# i2c1_secure register map
Vendor: Texas Instruments
Peripheral module from a debugger description file (folder CC35X1E).
Registers are 32-bit, access per field, reset values left out (the file's numbers can be read two ways) unless marked. A register's access mark holds for its fields unless they carry their own. Offsets are as the file gives them; lines under a group give offsets from that group; [hi:lo] are bit positions; {n}, {i} and the like mark numbered series; 'fields as' and 'values as' point back to an identical list; <NAME> marks a mode.

## i2c1_secure
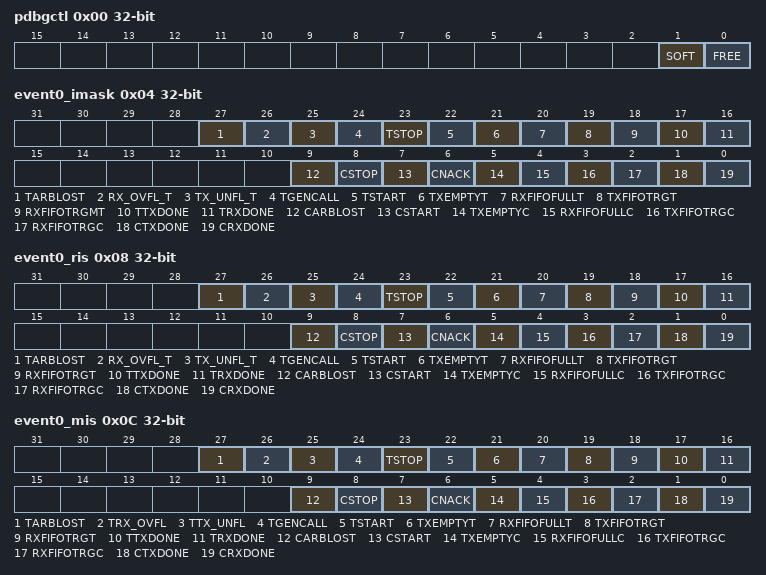
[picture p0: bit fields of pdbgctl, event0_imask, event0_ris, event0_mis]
0x00 pdbgctl — This register can be used by the software developer to control the behavior of the peripheral relative to the 'Core Halted' input
  [1] SOFT rw — Soft halt boundary control. This function is only available, if FREE is set to 'STOP'
    0=DIS (The peripheral will halt immediately, even if the resultant state will result in corruption if the system is restarted); 1=EN (The peripheral blocks the debug freeze until it has reached a boundary where it can resume without corruption)
  [0] FREE rw — Free run control
    0=DIS (The peripheral freezes functionality while the Core Halted input is asserted and resumes when it is deasserted.); 1=EN (The peripheral ignores the state of the Core Halted input)
0x04 event0_imask — Interrupt Mask. If a field is set, then corresponding interrupt is masked. Un-masking the interrupt causes the raw interrupt to be visible in [RIS], as well as [MIS].
  [27] TARBLOST rw — Target arbitration lost
    1=EN (Set Interrupt Mask); 0=DIS (Clear Interrupt Mask)
  [26] RX_OVFL_T rw — RX FIFO overflow in target mode
    1=EN (Set Interrupt Mask); 0=DIS (Clear Interrupt Mask)
  [25] TX_UNFL_T rw — TX FIFO underflow in target mode
    1=EN (Set Interrupt Mask); 0=DIS (Clear Interrupt Mask)
  [24] TGENCALL rw — General call interrupt
    1=EN (Set Interrrupt Mask); 0=DIS (Clear Interrupt Mask)
  [23] TSTOP rw — Stop condition interrupt
    1=EN (Set Interrrupt Mask); 0=DIS (Clear Interrupt Mask)
  [22] TSTART rw — Target start condition interrupt. Asserted when the received address matches the target address
    1=EN (Set Interrrupt Mask); 0=DIS (Clear Interrupt Mask)
  [21] TXEMPTYT rw — TX FIFO empty interrupt mask in target mode. This interrupt is set if all data in the Transmit FIFO in target mode have been shifted out and the transmit goes into idle mode.
    1=EN (Set Interrrupt Mask); 0=DIS (Clear Interrupt Mask)
  [20] RXFIFOFULLT rw — RX FIFO full event. This interrupt is set if an target RX FIFO is full in target mode.
    1=EN (Set Interrrupt Mask); 0=DIS (Clear Interrupt Mask)
  [19] TXFIFOTRGT rw — TX FIFO trigger in target mode
    1=EN (Set Interrrupt Mask); 0=DIS (Clear Interrupt Mask)
  [18] RXFIFOTRGMT rw — RX FIFO trigger in target mode
    1=EN (Set Interrrupt Mask); 0=DIS (Clear Interrupt Mask)
  [17] TTXDONE rw — Target transmit transaction completed interrupt
    1=EN (Set Interrrupt Mask); 0=DIS (Clear Interrupt Mask)
  [16] TRXDONE rw — Target receive data interrupt. Signals that a byte has been received
    1=EN (Set Interrrupt Mask); 0=DIS (Clear Interrupt Mask)
  [9] CARBLOST rw — Arbitration lost interrupt
    1=EN (Set Interrrupt Mask); 0=DIS (Clear Interrupt Mask)
  [8] CSTOP rw — STOP detection interrupt
    1=EN (Set Interrrupt Mask); 0=DIS (Clear Interrupt Mask)
  [7] CSTART rw — START detection interrupt
    1=EN (Set Interrrupt Mask); 0=DIS (Clear Interrupt Mask)
  [6] CNACK rw — Address/Data NACK interrupt
    1=EN (Set Interrrupt Mask); 0=DIS (Clear Interrupt Mask)
  [5] TXEMPTYC rw — TXFIFO empty interrupt in controller mode. This interrupt is set if all data in the TX FIFO in controller mode have been shifted out and the transmit goes into idle mode.
    1=EN (Set Interrrupt Mask); 0=DIS (Clear Interrupt Mask)
  [4] RXFIFOFULLC rw — RXFIFO full event in controller mode. This interrupt is set if an RX FIFO is full in controller mode.
    1=EN (Set Interrrupt Mask); 0=DIS (Clear Interrupt Mask)
  [3] TXFIFOTRGC rw — Transmit FIFO trigger in controller mode Trigger when TX FIFO contains <= defined bytes
    1=EN (Set Interrrupt Mask); 0=DIS (Clear Interrupt Mask)
  [2] RXFIFOTRGC rw — Receive FIFO trigger in controller code Trigger when RX FIFO contains >= defined bytes
    1=EN (Set Interrrupt Mask); 0=DIS (Clear Interrupt Mask)
  [1] CTXDONE rw — Controller transmit transaction completed Interrupt
    1=EN (Set Interrrupt Mask); 0=DIS (Clear Interrupt Mask)
  [0] CRXDONE rw — Controller receive transaction completed Interrupt
    1=EN (Set Interrrupt Mask); 0=DIS (Clear Interrupt Mask)
0x08 event0_ris ro — Raw interrupt status. Reflects all pending interrupts, regardless of masking. The RIS register allows the user to implement a poll scheme. A flag set in this register can be cleared by writing 1 to the [ICLR] register field even if the corresponding [IMASK] field is not enabled.
  [27] TARBLOST — Target arbitration lost
    1=SET (Interrupt occured); 0=CLR (Interrupt did not occur)
  [26] RX_OVFL_T — RX FIFO overflow in target mode
    1=SET (Interrupt Occured); 0=CLR (Interrupt did not occur)
  [25] TX_UNFL_T — TX FIFO underflow in target mode
    1=SET (Interrupt occured); 0=CLR (Interrupt did not occur)
  [24] TGENCALL — General call interrupt
    1=SET (Interrupt occured); 0=CLR (Interrupt did not occur)
  [23] TSTOP — Stop condition interrupt
    1=SET (Interrupt occured); 0=CLR (Interrupt did not occur)
  [22] TSTART — Target start condition interrupt.When the received address matches the target address, this interrupt asserted.
    1=SET (Interrupt occured); 0=CLR (Interrupt did not occur)
  [21] TXEMPTYT — TX FIFO empty interrupt mask in target mode. This interrupt is set if all data in the TX FIFO in target mode have been shifted out and the transmit goes into idle mode.
    1=SET (Interrupt occured); 0=CLR (Interrupt did not occur)
  [20] RXFIFOFULLT — RX FIFO full event in target mode. This interrupt is set if an RX FIFO is full in target mode.
    1=SET (Interrupt occured); 0=CLR (Interrupt did not occur)
  [19] TXFIFOTRGT — TX FIFO trigger in target mode
    1=SET (Interrupt occured); 0=CLR (Interrupt did not occur)
  [18] RXFIFOTRGT — RX FIFO trigger in target mode
    1=SET (Interrupt occured); 0=CLR (Interrupt did not occur)
  [17] TTXDONE — Target transmit transaction completed interrupt
    1=SET (Interrupt occured); 0=CLR (Interrupt did not occur)
  [16] TRXDONE — Target receive data interrupt. Signals that a byte has been received
    1=SET (Interrupt occured); 0=CLR (Interrupt did not occur)
  [9] CARBLOST — Arbitration lost interrupt
    1=SET (Interrupt occured); 0=CLR (Interrupt did not occur)
  [8] CSTOP — STOP detection interrupt
    1=SET (Interrupt occured); 0=CLR (Interrupt did not occur)
  [7] CSTART — START detection interrupt
    1=SET (Interrupt occured); 0=CLR (Interrupt did not occur)
  [6] CNACK — Address/Data NACK interrupt
    1=SET (Interrupt occured); 0=CLR (Interrupt did not occur)
  [5] TXEMPTYC — TX FIFO empty interrupt mask in controller mode. This interrupt is set if all data in the TX FIFO in controller mode have been shifted out and the transmit goes into idle mode.
    1=SET (Interrupt occured); 0=CLR (Interrupt did not occur)
  [4] RXFIFOFULLC — RX FIFO full event in controller mode. This interrupt is set if an RX FIFO is full in controller mode.
    1=SET (Interrupt occured); 0=CLR (Interrupt did not occur)
  [3] TXFIFOTRGC — TX FIFO Trigger in Transmit Mode Trigger when TX FIFO contains <= defined bytes
    1=SET (Interrupt occured); 0=CLR (Interrupt did not occur)
  [2] RXFIFOTRGC — RX FIFO trigger in controller mode Trigger when RX FIFO contains >= defined bytes
    1=SET (Interrupt occured); 0=CLR (Interrupt did not occur)
  [1] CTXDONE — Controller transmit transaction completed interrupt
    1=SET (Interrupt occured); 0=CLR (Interrupt did not occur)
  [0] CRXDONE — Controller receive transaction completed interrupt
    1=SET (Interrupt occured); 0=CLR (Interrupt did not occur)
0x0C event0_mis ro — Masked interrupt status. This is an AND of the [IMASK] and [RIS] registers.
  [27] TARBLOST — Target arbitration lost
    1=SET (Masked interrupt occured); 0=CLR (Clear interrupt mask)
  [26] TRX_OVFL — RX FIFO overflow in target mode
    1=SET (Masked interrupt occured); 0=CLR (Masked Interrupt did not occur)
  [25] TTX_UNFL — TX FIFO underflow in target mode
    values as TRX_OVFL
  [24] TGENCALL — General call interrupt
    values as TRX_OVFL
  [23] TSTOP — Target STOP detection interrupt
    values as TRX_OVFL
  [22] TSTART — Target start condition interrupt. Asserted when the received address matches the target address
    values as TRX_OVFL
  [21] TXEMPTYT — TX FIFO empty interrupt mask in target mode. This interrupt is set if all data in the TX FIFO in target mode have been shifted out and the transmit goes into idle mode.
    values as TRX_OVFL
  [20] RXFIFOFULLT — RXFIFO full event in Target mode. This interrupt is set if an RX FIFO is full in target mode.
    values as TRX_OVFL
  [19] TXFIFOTRGT — TX FIFO trigger in target mode
    values as TRX_OVFL
  [18] RXFIFOTRGT — Target RX FIFO trigger
    values as TRX_OVFL
  [17] TTXDONE — Target transmit transaction completed interrupt
    values as TRX_OVFL
  [16] TRXDONE — Target receive data interrupt. Signals that a byte has been received
    values as TRX_OVFL
  [9] CARBLOST — Arbitration lost interrupt
    values as TRX_OVFL
  [8] CSTOP — STOP detection interrupt
    values as TRX_OVFL
  [7] CSTART — START detection interrupt
    values as TRX_OVFL
  [6] CNACK — Address/Data NACK interrupt
    values as TRX_OVFL
  [5] TXEMPTYC — TX FIFO Empty interrupt mask in controller mode. This interrupt is set if all data in the TX FIFO in controller mode have been shifted out and the transmit goes into idle mode.
    values as TRX_OVFL
  [4] RXFIFOFULLC — RX FIFO full event. This interrupt is set if the RX FIFO is full in controller mode.
    values as TRX_OVFL
  [3] TXFIFOTRGC — TX FIFO trigger in controller mode Trigger when TX FIFO contains <= defined bytes
    values as TRX_OVFL
  [2] RXFIFOTRGC — RX FIFO trigger in controller mode Trigger when RX FIFO contains >= defined bytes
    values as TRX_OVFL
  [1] CTXDONE — Controller transmit transaction completed interrupt
    values as TRX_OVFL
  [0] CRXDONE — Controller receive data interrupt
    values as TRX_OVFL
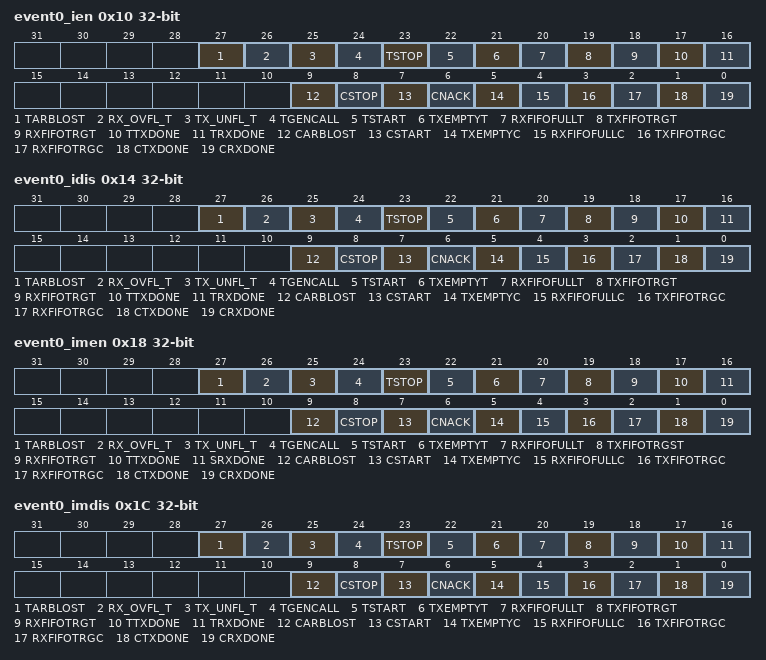
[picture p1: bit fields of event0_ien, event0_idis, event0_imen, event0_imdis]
0x10 event0_ien — Interrupt set. Allows interrupts to be set by software (useful in diagnostics and safety checks). Writing a 1 to a field in IEN will set the event and therefore the related RIS field also gets set. If the interrupt is enabled through the mask, then the corresponding MIS field is also set.
  [27] TARBLOST wo — Target arbitration lost
    1=EN (Set Interrupt); 0=DIS (Writing 0 has no effect)
  [26] RX_OVFL_T wo — RX FIFO overflow in target mode
    1=EN (Set Interrrupt); 0=DIS (Writing 0 has no effect)
  [25] TX_UNFL_T wo — TX FIFO underflow in target mode
    1=EN (Set interrupt); 0=DIS (Writing 0 has no effect)
  [24] TGENCALL wo — General call interrupt
    1=EN (Set Interrrupt); 0=DIS (Writing 0 has no effect)
  [23] TSTOP wo — Stop condition interrupt
    1=EN (Set Interrrupt); 0=DIS (Writing 0 has no effect)
  [22] TSTART wo — Target start condition interrupt. Asserted when the received address matches the target address
    1=EN (Set Interrrupt); 0=DIS (Writing 0 has no effect)
  [21] TXEMPTYT wo — TX FIFO empty interrupt mask in target mode. This interrupt is set if all data in the TX FIFO in target mode have been shifted out and the transmit goes into idle mode.
    1=EN (Set Interrrupt); 0=DIS (Writing 0 has no effect)
  [20] RXFIFOFULLT wo — RXFIFO full event in Target mode. This interrupt is set if an RX FIFO is full in Target mode.
    1=EN (Set Interrrupt); 0=DIS (Writing 0 has no effect)
  [19] TXFIFOTRGT wo — TX FIFO trigger in target mode
    1=EN (Set Interrrupt); 0=DIS (Writing 0 has no effect)
  [18] RXFIFOTRGT wo — RX FIFO trigger in target mode
    1=EN (Set Interrrupt); 0=DIS (Writing 0 has no effect)
  [17] TTXDONE wo — Target transmit transaction completed Interrupt
    1=EN (Set Interrrupt); 0=DIS (Writing 0 has no effect)
  [16] TRXDONE wo — Target receive data interrupt. Signals that a byte has been received
    1=EN (Set Interrrupt); 0=DIS (Writing 0 has no effect)
  [9] CARBLOST wo — Arbitration lost interrupt
    1=EN (Set Interrrupt); 0=DIS (Writing 0 has no effect)
  [8] CSTOP wo — STOP detection interrupt
    1=EN (Set Interrrupt); 0=DIS (Writing 0 has no effect)
  [7] CSTART wo — START detection interrupt
    1=EN (Set Interrrupt); 0=DIS (Writing 0 has no effect)
  [6] CNACK wo — Address/Data NACK interrupt
    1=EN (Set Interrrupt); 0=DIS (Writing 0 has no effect)
  [5] TXEMPTYC wo — TX FIFO empty interrupt mask in controller mode. This interrupt is set if all data in the TX FIFO in controller mode have been shifted out and the transmit goes into idle mode.
    1=EN (Set Interrrupt); 0=DIS (Writing 0 has no effect)
  [4] RXFIFOFULLC wo — RXFIFO full event in controller mode.
    1=EN (Set Interrrupt); 0=DIS (Writing 0 has no effect)
  [3] TXFIFOTRGC wo — TX FIFO trigger in controller mode Trigger when TX FIFO contains <= defined bytes
    1=EN (Set Interrrupt); 0=DIS (Writing 0 has no effect)
  [2] RXFIFOTRGC wo — RX FIFO trigger in controller mode Trigger when RX FIFO contains >= defined bytes
    1=EN (Set Interrrupt); 0=DIS (Writing 0 has no effect)
  [1] CTXDONE wo — Controller transmit transaction completed interrupt
    1=EN (Set Interrrupt); 0=DIS (Writing 0 has no effect)
  [0] CRXDONE wo — Controller receive data interrupt Signals that a byte has been received
    1=EN (Set Interrrupt); 0=DIS (Writing 0 has no effect)
0x14 event0_idis — Interrupt clear. Write a 1 to clear corresponding Interrupt.
  [all] fields
    1=EN (Clear Interrupt); 0=DIS (Writing 0 has no effect)
  [27] TARBLOST wo — Target arbitration lost
  [26] RX_OVFL_T wo — RX FIFO overflow in target mode
  [25] TX_UNFL_T wo — TX FIFO underflow in target mode
  [24] TGENCALL wo — General call interrupt
  [23] TSTOP wo — Target STOP detection interrupt
  [22] TSTART wo — Target start condition interrupt. Asserted when the received address matches the target address
  [21] TXEMPTYT wo — TX FIFO empty interrupt mask in target mode. This interrupt is set if all data in the TX FIFO in target mode have been shifted out and the transmit goes into idle mode.
  [20] RXFIFOFULLT wo — RXFIFO full event in target mode. This interrupt is set if an RX FIFO is full in target mode.
  [19] TXFIFOTRGT wo — TX FIFO trigger in target mode
  [18] RXFIFOTRGT wo — RX FIFO trigger in target mode
  [17] TTXDONE wo — Target transmit transaction completed interrupt
  [16] TRXDONE wo — Target receive data interrupt Signals that a byte has been received
  [9] CARBLOST wo — Arbitration lost interrupt
  [8] CSTOP wo — STOP detection interrupt
  [7] CSTART wo — START detection interrupt
  [6] CNACK wo — Address/Data NACK interrupt
  [5] TXEMPTYC wo — TX FIFO empty interrupt mask. This interrupt is set if all data in the TX FIFO have been shifted out and the transmit goes into idle mode.
  [4] RXFIFOFULLC wo — RXFIFO full event in controller mode.
  [3] TXFIFOTRGC wo — TX FIFO trigger in controller mode Trigger when TX FIFO contains <= defined bytes
  [2] RXFIFOTRGC wo — RX FIFO trigger in controller mode Trigger when RX FIFO contains >= defined bytes
  [1] CTXDONE wo — Controller transmit transaction completed interrupt
  [0] CRXDONE wo — Controller receive data interrupt. Signals that a byte has been received
0x18 event0_imen — Interrupt mask set. Writing a 1 to a field in IMEN will set the related IMASK field.
  [all] fields
    1=EN (Set masked interrrupt); 0=DIS (Writing 0 has no effect)
  [27] TARBLOST wo — Target srbitration lost
  [26] RX_OVFL_T wo — RX FIFO overflow in target mode
  [25] TX_UNFL_T wo — TX FIFO underflow in target mode
  [24] TGENCALL wo — General call interrupt
  [23] TSTOP wo — Stop condition interrupt
  [22] TSTART wo — Target start condition interrupt. Asserted when the received address matches the target address
  [21] TXEMPTYT wo — TX FIFO Empty interrupt mask in target mode. This interrupt is set if all data in the TX FIFO in target mode have been shifted out and the transmit goes into idle mode.
  [20] RXFIFOFULLT wo — RXFIFO full event in target mode. This interrupt is set if an RX FIFO is full in target mode.
  [19] TXFIFOTRGST wo — TX FIFO trigger in target mode
  [18] RXFIFOTRGT wo — RX FIFO trigger in target mode
  [17] TTXDONE wo — Target transmit transaction completed interrupt
  [16] SRXDONE wo — Target receive data interrupt. Signals that a byte has been received
  [9] CARBLOST wo — Arbitration lost interrupt
  [8] CSTOP wo — STOP detection interrupt
  [7] CSTART wo — START detection interrupt
  [6] CNACK wo — Address/Data NACK interrupt
  [5] TXEMPTYC wo — TX FIFO empty interrupt mask in controller mode. This interrupt is set if all data in the TX FIFO in controller mode have been shifted out and the transmit goes into idle mode.
  [4] RXFIFOFULLC wo — RXFIFO full event in controller mode.
  [3] TXFIFOTRGC wo — TX FIFO trigger in Controller mode Trigger when TX FIFO contains <= defined bytes
  [2] RXFIFOTRGC wo — RX FIFO trigger in controller mode Trigger when RX FIFO contains >= defined bytes
  [1] CTXDONE wo — Controller transmit transaction completed interrupt
  [0] CRXDONE wo — Controller receive data interrupt. Signals that a byte has been received
0x1C event0_imdis — Interrupt clear. Write a 1 to clear corresponding Interrupt.
  [all] fields
    1=EN (Clear masked interrupt); 0=DIS (Writing 0 has no effect)
  [27] TARBLOST wo — Target arbitration lost
  [26] RX_OVFL_T wo — RX FIFO overflow in target mode
  [25] TX_UNFL_T wo — TX FIFO underflow in target mode
  [24] TGENCALL wo — General call interrupt
  [23] TSTOP wo — Target STOP detection interrupt
  [22] TSTART wo — Target start condition interrupt. Asserted when the received address matches the target address.
  [21] TXEMPTYT wo — TX FIFO empty interrupt mask in target mode. This interrupt is set if all data in the TX FIFO in target mode have been shifted out and the transmit goes into idle mode.
  [20] RXFIFOFULLT wo — RXFIFO full event in target mode. This interrupt is set if an RX FIFO is full in target mode.
  [19] TXFIFOTRGT wo — TX FIFO trigger in target mode
  [18] RXFIFOTRGT wo — RX FIFO trigger in target mode
  [17] TTXDONE wo — Target transmit transaction completed interrupt
  [16] TRXDONE wo — Target receive data interrupt. Signals that a byte has been received
  [9] CARBLOST wo — Arbitration lost interrupt
  [8] CSTOP wo — STOP detection interrupt
  [7] CSTART wo — START detection interrupt
  [6] CNACK wo — Address/Data NACK interrupt
  [5] TXEMPTYC wo — TX FIFO empty interrupt mask. This interrupt is set if all data in the TX FIFO have been shifted out and the transmit goes into idle mode.
  [4] RXFIFOFULLC wo — RX FIFO full event in controller mode.
  [3] TXFIFOTRGC wo — TX FIFO trigger in controller mode Trigger when TX FIFO contains <= defined bytes
  [2] RXFIFOTRGC wo — RX FIFO trigger in controller mode Trigger when RX FIFO contains >= defined bytes
  [1] CTXDONE wo — Controller transmit transaction completed interrupt
  [0] CRXDONE wo — Controller receive data interrupt. Signals that a byte has been received
0x20 evt_mode ro — Event mode register. It is used to select whether each line is disabled, in software mode (software clears the [RIS]) or in hardware mode (hardware clears the [RIS])
  [1:0] INT0_CFG — Event line mode select for event corresponding to [INT_EVENT0]
    0=DIS (The interrupt or event line is disabled.); 1=SOFTWARE (The interrupt or event line is in software mode. Software must clear the RIS.); 2=HARDWARE (The interrupt or event line is in hardware mode. The hardware (another module) clears automatically the associated RIS flag.)
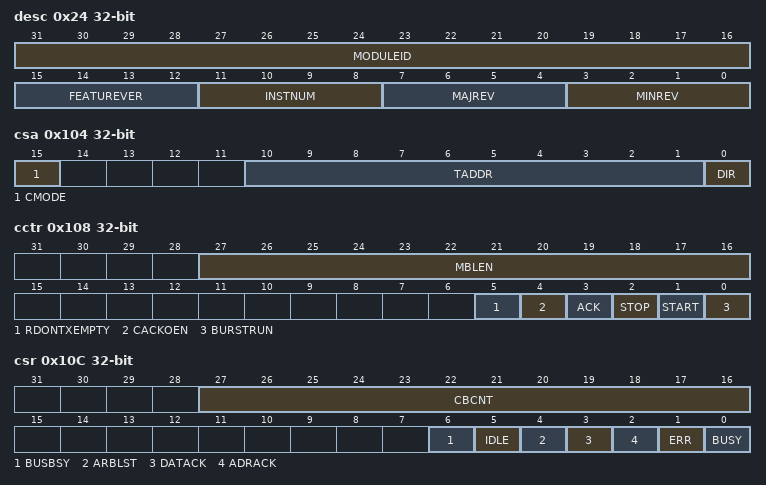
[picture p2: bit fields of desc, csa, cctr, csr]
0x24 desc ro — This register identifies the peripheral and its exact version.
  [31:16] MODULEID — Module identification contains a unique peripheral identification number. The assignments are maintained in a central database for all of the platform modules to ensure uniqueness.
    0=MINIMUM (Smallest value); 0xFFFF=MAXIMUM (Highest possible value)
  [15:12] FEATUREVER — Feature Set for the module *instance*
    0=MINIMUM (Smallest value); 15=MAXIMUM (Highest possible value)
  [11:8] INSTNUM — Instance Number within the device. This will be a parameter to the RTL for modules that can have multiple instances
    values as FEATUREVER
  [7:4] MAJREV — Major rev of the IP
    values as FEATUREVER
  [3:0] MINREV — Minor rev of the IP
    values as FEATUREVER
0x100 gfctl — This register controls the glitch filter on the SCL and SDA lines
  [3:0] GFSEL rw — Glitch suppression pulse width This field controls the pulse width select for glitch suppression on the SCL and SDA lines. The following values are the glitch suppression values in terms of functional clocks.
    0=DIS (Bypass); 1=CLK_1 (1 clock); {v}=CLK_{v} ({v} clocks) (v=2..8); 9=CLK_9 (10 clocks); 10=CLK_A (12 clocks); 11=CLK_B (14 clocks); 12=CLK_C (16 clocks); 13=CLK_D (20 clocks); 14=CLK_E (24 clocks); 15=CLK_F (31 clocks)
0x104 csa — Controller target address register
  [15] CMODE rw — This field selects the addressing mode(7-field/10-field) to be used in controller mode
    0=SEVEN_BIT (7-field addressing mode); 1=TEN_BIT (10-field addressing mode)
  [10:1] TADDR rw — *I2C* Target Address This field specifies bits A9 through A0 of the target address. In 7-field addressing mode as selected by MODE field, the top 3 bits are don't care
    0=MINIMUM (Smallest value); 0x3FF=MAXIMUM (Highest possible value)
  [0] DIR rw — This field specifies if the next controller operation is a Receive or Transmit
    0=TRANSMIT (The controller is in transmit mode.); 1=RECEIVE (The controller is in receive mode.)
0x108 cctr — This control register configures the *I2C* controller operation. The START field generates the START or REPEATED START condition. The STOP field determines if the cycle stops at the end of the data cycle or continues to the next transfer cycle, which could be a repeated START. To generate a single transmit cycle, the *I2C* Controller Target Address [CSA] register is written with the desired address, the RS field is cleared, and this register is written with ACK = X (0 or 1), STOP = 1, START = 1, and RUN = 1 to perform the operation and stop. When the operation is completed (or aborted due an error), an byte transaction completed interrupt becomes active and the data may be read from the RXDATA register. When the I2C module operates in Controller receiver mode, a set ACK field causes the I2C bus controller to transmit an acknowledge automatically after each byte. This field must be cleared when the *I2C* bus controller requires no further data to be transmitted from the target transmitter.
  [27:16] MBLEN rw — Transaction length This field contains the programmed length of bytes of the Transaction.
    0=MINIMUM (Smallest value); 0xFFF=MAXIMUM (Highest possible value)
  [5] RDONTXEMPTY rw — Read on TXFIFO empty
    1=EN (When 1 the controller will transmit all bytes from the TX FIFO before continuing with the programmed Burst Run Read. If the [CSA.DIR] is not set to read, then this field is ignored. The Start must be set in the [CCTR] for proper *I2C* protocol. The controller will first send the Start Condition, *I2C* Address with R/W field set to write, before sending the bytes in the TX FIFO. When the TX FIFO is empty, the *I2C* transaction will continue as programmed in [CCTR] and [CSA] without sending a Stop Condition. This is intended to be used to perform simple *I2C* command based reads transition that will complete after initiating them without having to get an interrupt to turn the bus around.); 0=DIS (No special behaviour)
  [4] CACKOEN rw — Controller ACK overrride enable
    1=EN (When 1 and the controller is receiving data and the number of bytes indicated in MBLEN have been received, the state machine will generate an rxdone interrupt and wait at the start of the ACK for FW to indicate if an ACK or NACK should be sent. The ACK or NACK is selected by writing the [CCTR] register and setting ACK accordingly. The other fields in this register can also be written at this time to continue on with the transaction. If a NACK is sent the state machine will automatically send a Stop.); 0=DIS (No special behavior)
  [3] ACK rw — Data Acknowledge Enable. Configure this field to send the ACK or NACK.
    0=DIS_ACK (The last received data byte of a transaction is not acknowledged automatically by the controller.); 1=EN_ACK (The last received data byte of a transaction is acknowledged automatically by the controller.)
  [2] STOP rw — Generate STOP
    0=DIS_STOP (The controller does not generate the STOP condition.); 1=EN_STOP (The controller generates the STOP condition)
  [1] START rw — Generate START
    0=DIS_START (The controller does not generate the START condition.); 1=EN_START (The controller generates the START or repeated START condition)
  [0] BURSTRUN rw — Controller enable and start transaction
    0=DIS (In standard mode, the controller will be unable to transmit or receive data.); 1=EN (The controller will be able to transmit or receive data)
0x10C csr ro — The status register indicates the state of the bus controller.
  [27:16] CBCNT — Controller Transaction Count This field contains the current count-down value of the transaction.
    0xFFF=MAXIMUM (Highest possible value); 0=MINIMUM (Smallest value)
  [6] BUSBSY — Bus is busy Controller state machine will wait until this field is cleared before starting a transaction. When first enabling the controller in multi controller environments, FW should wait for one I2C clock period after setting ACTIVE high before writing to the [CCTR] register to start the transaction so that if SCL goes low it will trigger the BUSBSY.
    0=CLEAR (The bus is idle.); 1=SET (This Status field is set on a START or when SCL goes low. It is cleared on a STOP, or when a SCL high bus busy timeout occurs and SCL and SDA are both high. This status is cleared when the ACTIVE field is low. Note that the controller state machine will wait until this field is cleared before starting a transaction. When first enabling the controller in multi controller environments, FW should wait for one I2C clock period after setting ACTIVE high before writing to the [CCTR] register to start the transaction so that if SCL goes low it will trigger the BUSBSY.)
  [5] IDLE — *I2C* Idle
    0=CLEAR (The controller is not idle.); 1=SET (The controller is idle.)
  [4] ARBLST — Arbitration lost
    0=CLEAR (The controller won arbitration.); 1=SET (The controller lost arbitration.)
  [3] DATACK — Acknowledge data
    0=CLEAR (The transmitted data was acknowledged); 1=SET (The transmitted data was not acknowledged.)
  [2] ADRACK — Acknowledge address
    0=CLEAR (The transmitted address was acknowledged); 1=SET (The transmitted address was not acknowledged.)
  [1] ERR — Error The error can be from the target address not being acknowledged or the transmit data not being acknowledged.
    0=CLEAR (No error was detected on the last operation.); 1=SET (An error occurred on the last operation.)
  [0] BUSY — Controller FSM busy The field is set during an ongoing transaction, so is set during the transmit/receive of the amount of data set in [CCTR.MBLEN] including START, RESTART, Address and STOP signal generation when required for the current transaction.
    0=CLEAR (The controller is idle.); 1=SET (The controller is busy.)
0x110 ctpr — This register is programmed to set the timer period for the SCL clock and assign the SCL clock to standard mode.
  [6:0] TPR rw — Timer Period This field is used in the equation to configure SCL_PERIOD : SCL_PERIOD = (1 + TPR ) x (SCL_LP + SCL_HP ) x INT_CLK_PRD where: SCL_PRD is the SCL line period (I2C clock). TPR is the Timer Period register value (range of 1 to 127). SCL_LP is the SCL Low period (fixed at 6). SCL_HP is the SCL High period (fixed at 4). INT_CLK_PRD is the functional clock period in ns. Note: INT_CLK_PRD is based on divider value selected in [FCLK_DIV:FCLK:DIV]
    0=MINIMUM (Smallest value); 127=MAXIMUM (Highest possible value)
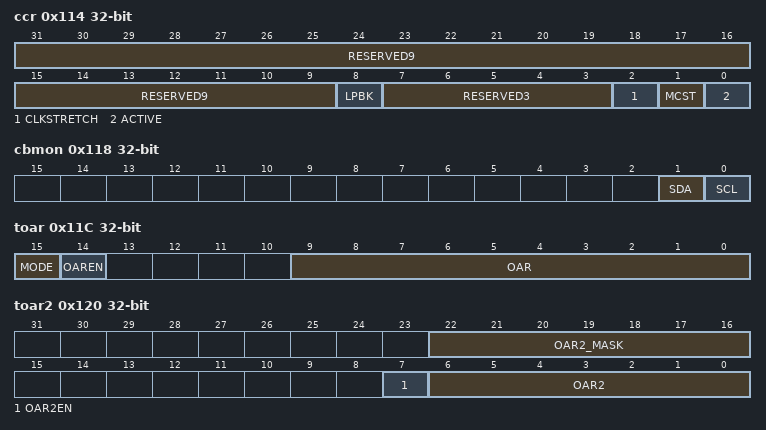
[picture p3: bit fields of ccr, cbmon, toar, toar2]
0x114 ccr — Controller configuration register
  [31:9] RESERVED9 ro — Reads to this field return zero.Writes to this field are ignored.
  [8] LPBK rw — I2C Loopback
    0=DIS (Normal operation.); 1=EN (The controller in a test mode loopback configuration.)
  [7:3] RESERVED3 ro — Reads to this field return zero.Writes to this field are ignored.
  [2] CLKSTRETCH rw — Clock Stretching. This field controls the support for clock stretching of the *I2C* bus.
    0=DIS (Disables the clock stretching detection. This can be disabled if no target on the bus does support clock streching, so that the maximum speed on the bus can be reached.); 1=EN (Enables the clock stretching detection. Enabling the clock strechting ensures compliance to the I2C standard but could limit the speed due the clock stretching.)
  [1] MCST rw — Multicontroller mode. In Multicontroller mode the SCL high time counts once the SCL line has been detected high. If this is not enabled the high time counts as soon as the SCL line has been set high by the *I2C* controller.
    0=DIS (Disable Multicontroller mode.); 1=EN (Enable Multicontroller mode.)
  [0] ACTIVE rw — Device Active After this field has been set, it should not be set again unless it has been cleared by writing a 0 or by a reset, otherwise transfer failures may occur.
    0=DIS (Disables the *I2C* controller operation.); 1=EN (Enables the *I2C* controller operation.)
0x118 cbmon ro — This register is used to determine the SCL and SDA signal status.
  [1] SDA — SDA status
    0=CLEAR (The SDA signal is low.); 1=SET (The SDA signal is high. Note: During and right after reset, the SDA pin is in GPIO input mode without the internal pull enabled. For proper *I2C* operation, the user should have the external pull-up resistor in place.)
  [0] SCL — SCL status
    0=CLEAR (The SCL signal is low.); 1=SET (The SCL signal is high Note: During and right after reset, the SCL pin is in GPIO input mode without the internal pull enabled. For proper *I2C* operation, the user should have the external pull-up resistor in place.)
0x11C toar — This register consists of seven address bits that identify the I2C device on the I2C bus.
  [15] MODE rw — This field selects the addressing mode(7-field/10-field) to be used in target mode.
    0=SEVEN_BIT (Enable 7-field addressing); 1=TEN_BIT (Enable 10-field addressing)
  [14] OAREN rw — Target own address enable
    1=EN (Enable OAR address); 0=DIS (Disable OAR address)
  [9:0] OAR rw — Target own address: This field specifies bits A9 through A0 of the target address. In 7-field addressing mode as selected by [TOAR.MODE] field, the top 3 bits are don't care
    values as csa.TADDR
0x120 toar2 — This register consists of seven address bits that identify the alternate address for the *I2C* device on the *I2C* bus.
  [22:16] OAR2_MASK rw — Target own address 2 mask: This field specifies bits A6 through A0 of the target address. The bits with value '1' in this field will make the corresponding incoming address bits to match by default regardless of the value inside this field i.e. corresponding bits of this field are don't care.
    0=MINIMUM (Minimum Value); 127=MAXIMUM (Maximum Value)
  [7] OAR2EN rw — Target own address 2 enable
    0=DIS (The alternate address is disabled.); 1=EN (Enables the use of the alternate address in the OAR2 field.)
  [6:0] OAR2 rw — Target own address 2 This field specifies the alternate target own address.
    values as ctpr.TPR
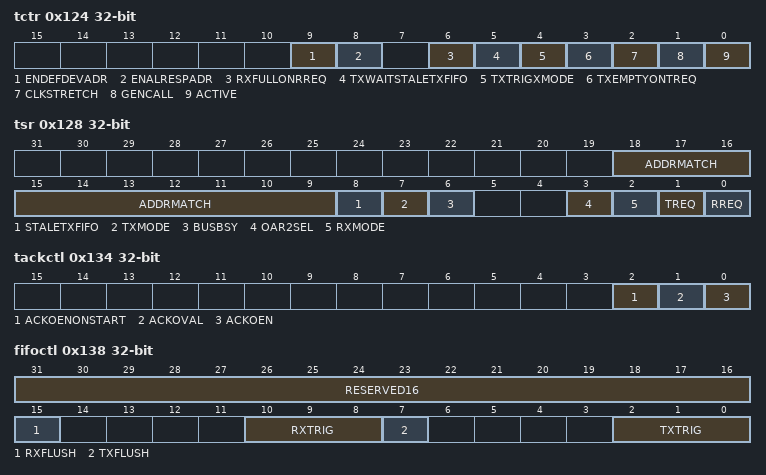
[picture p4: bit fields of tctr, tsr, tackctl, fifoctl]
0x124 tctr — Target control register
  [9] ENDEFDEVADR rw — Enable default device address
    1=EN (When this field is 1, default device address of 7'h110_0001 is always matched by the target address match logic.); 0=DIS (When this field is 0, the default device address is not matched. NOTE: it may still be matched if programmed inside TOAR/TOAR2.)
  [8] ENALRESPADR rw — Enable alert response address
    1=EN (Alert response address of 7'h000_1100 is always matched by the target address match logic.); 0=DIS (The alert response address is not matched. NOTE: It may still be matched if programmed inside [TOAR]/[TOAR2])
  [6] RXFULLONRREQ rw — Rx full interrupt generated based on [TSR.RREQ] filed.
    1=EN ([RIS.SRXFULL] will be set when the target state machine is in the RX_WAIT or RX_ACK_WAIT states which occurs when the transaction is clock stretched because the RX FIFO is full or the ACKOEN has been set and the state machine is waiting for FW to ACK/NACK the current byte.); 0=DIS ([RIS.TRXFULL] will be set when only the Target RX FIFO is full. This allows the [RIS.TRXFULL] interrupt to be used to indicate that the I2C bus is being clock stretched and that the FW must either read the RX FIFO or ACK/NACK the current RX byte.)
  [5] TXWAITSTALETXFIFO rw — Tx transfer waits when stale data in Tx FIFO. This prevents stale bytes left in the TX FIFO from automatically being sent on the next I2C packet. Note: this should be used with [TCTR:TXEMPTY_ON_TREQ] set to prevent the Target State Machine from waiting for TX FIFO data without an interrupt notification when the FIFO data is stale.
    1=EN (The TX FIFO empty signal to the Target State Machine will indicate that the TX FIFO is empty or that the TX FIFO data is stale. The TX FIFO data is determined to be stale when there is data in the TX FIFO when the target state machine leaves the [TSR.TXMODE] field. This can occur is a stop or timeout occur when there are bytes left in the TX FIFO.); 0=DIS (The TX FIFO empty signal to the Target State Machine indicates that the TX FIFO is empty.)
  [4] TXTRIGXMODE rw — Tx trigger when target FSM is in TX mode
    1=EN ([RIS.TXFIFOTRG] will be set when the Target TX FIFO has reached the trigger level AND the target state machine is in the as defined in the [TSR.TXMODE] field. When cleared [RIS.TXFIFOTRG] will be set when the Target TX FIFO is at or above the trigger level. This setting can be used to hold off the TX DMA until a transaction starts. This allows the DMA to be configured when the *I2C* is idle but have it wait till the transaction starts to load the Target TX FIFO, so it can load from a memory buffer that might be changing over time.); 0=DIS (No special behavior)
  [3] TXEMPTYONTREQ rw — Tx Empty Interrupt on TREQ
    1=EN ([RIS.STXEMPTY] will be set when the Target State Machine is in the TX_WAIT state which occurs when the TX FIFO is empty and the transaction is clock stretched waiting for the FIFO to receive data.); 0=DIS ([RIS.TTXEMPTY] will be set when only the target TX FIFO is empty. This allows the [RIS.TTXEMPTY] interrupt to be used to indicate that the bus is being clock stretched and that target TX data is required.)
  [2] CLKSTRETCH rw — Target clock stretch enable
    1=EN (Target clock stretching is enabled); 0=DIS (Target clock stretching is disabled)
  [1] GENCALL rw — General call response enable.
    0=DIS (Do not respond to a general call); 1=EN (Respond to a general call)
  [0] ACTIVE rw — Device active. Setting this field enables the target functionality.
    0=DIS (Disables the target operation.); 1=EN (Enables the target operation.)
0x128 tsr ro — Target status register
  [18:9] ADDRMATCH — Indicates the address for which target address match happened
    0=MINIMUM (Minimum Value); 0x3FF=MAXIMUM (Maximum Value)
  [8] STALETXFIFO
    1=SET (The TX FIFO is stale. This occurs when the TX FIFO was not emptied during the previous transaction.); 0=CLEAR (Tx FIFO is not stale)
  [7] TXMODE — Target FSM is in TX MODE
    1=SET (The target state machine is in TX_DATA, TX_WAIT, TX_ACK or ADDR_ACK state with the bus direction set to read.); 0=CLEAR (The target state machine is not in TX_DATA, TX_WAIT, TX_ACK or ADDR_ACK state with the bus direction set to read.)
  [6] BUSBSY — Bus is busy
    1=SET (Bus is busy. This is cleared on a timeout.); 0=CLEAR (Bus is not busy)
  [3] OAR2SEL — OAR2 address matched This field gets re-evaluated after every address comparison.
    0=CLEAR (Either the OAR2 address is not matched or the match is in legacy mode.); 1=SET (OAR2 address matched and acknowledged by the target.)
  [2] RXMODE — Target FSM is in RX MODE
    1=SET (The target state machine is in the RX_DATA, RX_ACK, RX_WAIT, RX_ACK_WAIT or ADDR_ACK state with the bus direction set to write.); 0=CLEAR (The target state machine is not in the RX_DATA, RX_ACK, RX_WAIT, RX_ACK_WAIT or ADDR_ACK state with the bus direction set to write.)
  [1] TREQ — Transmit Request
    0=CLEAR (No outstanding transmit request.); 1=SET (The controller has been addressed as a target transmitter and is using clock stretching to delay the controller until data has been written to the TXDATA FIFO (Target TX FIFO is empty).)
  [0] RREQ — Receive Request
    0=CLEAR (No outstanding receive data.); 1=SET (The controller has outstanding receive data and is using clock stretching to delay the controller until the data has been read from the RXDATA FIFO (target RX FIFO is full).)
0x12C rxdata ro — RX FIFO read data byte This field contains the current byte being read in the RX FIFO stack. If the FIFO is disabled, the data byte and status are stored in the receiving holding register (the bottom word of the receive FIFO). The received data can be retrieved by reading this register.
  [7:0] VALUE — Received Data. This field contains the last received data.
    0=MINIMUM (Smallest value); 255=MAXIMUM (Highest possible value)
0x130 txdata — Transmit data register. This register is the transmit data register (the interface to the FIFOs). For transmitted data, if the FIFO is enabled, data written to this location is pushed onto the transmit FIFO. If the FIFO is disabled, data is stored in the transmitter holding register (the bottom word of the transmit FIFO).
  [7:0] VALUE rw — Transmit data This byte contains the data to be transferred during the next transaction.
    values as rxdata.VALUE
0x134 tackctl — This register enables the target to not acknowledge (NACK) for invalid data or command or acknowledge (ACK) for valid data or command. The *I2C* clock is pulled low after the last data field until this register is written.
  [2] ACKOENONSTART rw — When set this field will automatically turn on the target ACKOEN field following a start condition.
    1=EN (When set this field will automatically turn on the Target ACKOEN field following a start condition.); 0=DIS (No special behavior)
  [1] ACKOVAL rw — Target ACK override Value Note: For general call this field will be ignored if set to NACK and target continues to receive data.
    0=DIS (An ACK is sent indicating valid data or command.); 1=EN (A NACK is sent indicating invalid data or command.)
  [0] ACKOEN rw — Target ACK override enable
    0=DIS (A response in not provided.); 1=EN (An ACK or NACK is sent according to the value written to the ACKOVAL field.)
0x138 fifoctl — Target FIFO control
  [31:16] RESERVED16 ro — Reads to this field return zero.Writes to this field are ignored.
  [15] RXFLUSH rw — RX FIFO flush Setting this field will flush the RX FIFO. Before resetting this field to stop flush the [FIFOSR.RXFIFOCNT] should be checked to be 0 and indicating that the flush has completed.
    0=DIS (Do not flush FIFO); 1=EN (Flush FIFO)
  [10:8] RXTRIG rw — RX FIFO trigger Indicates at what fill level in the RX FIFO a trigger will be generated. Note: Programming this field to 0x0 has no effect since no data is present to transfer out of RX FIFO.
    {v}=LEVEL_{v+1} (Trigger when RX FIFO contains >= {v+1} byte) (v=0..7)
  [7] TXFLUSH rw — TX FIFO flush Setting this field will flush the TX FIFO. Before resetting this field to stop flush the TXFIFOCNT should be checked to be 8 and indicating that the flush has completed.
    0=DIS (Do not flush FIFO); 1=EN (flush FIFO)
  [2:0] TXTRIG rw — TX FIFO trigger Indicates at what fill level in the TX FIFO a trigger will be generated.
    0=EMPTY (Trigger when the TX FIFO is empty.); {v}=LEVEL_{v} (Trigger when TX FIFO contains bigger or equal to {v} byte) (v=1..7)
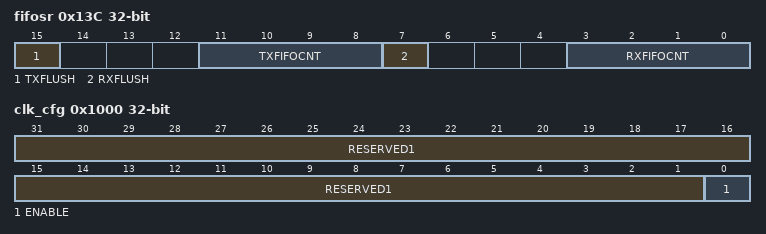
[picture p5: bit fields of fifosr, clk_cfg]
0x13C fifosr ro — FIFO status register Note: This register should only be read when BUSY is 0
  [15] TXFLUSH — TX FIFO flush When this field is set a flush operation for the TX FIFO is active. Clear [FIFOCTL.TXFLUSH] to stop.
    0=CLEAR (FIFO flush not active); 1=SET (FIFO flush active)
  [11:8] TXFIFOCNT — Number of bytes which could be put into the TX FIFO
    0=MINIMUM (Smallest value); 8=MAXIMUM (Highest possible value)
  [7] RXFLUSH — RX FIFO flush When this field is set a flush operation for the RX FIFO is active. Clear the [FIFOCTL.RXFLUSH] field to stop.
    0=CLEAR (FIFO flush not active); 1=SET (FIFO flush active)
  [3:0] RXFIFOCNT — Number of bytes which could be read from the RX FIFO
    values as TXFIFOCNT
0x140 fclk_div — Register for the selection of divider value to generate functional clock from SVT clock
  [3:0] FCLKDIV rw — Divider value selection
    0=BY_1 (Divide by 1 = 80MHz); 1=BY_2 (Divide by 2 = 40MHz); 2=BY_4 (Divide by 4 = 20MHz); 3=BY_5 (Divide by 5 = 16MHz); 4=BY_8 (Divide by 8 = 10MHz); 5=BY_10 (Divide by 10 = 8MHz); 6=BY_16 (Divide by 16 = 5MHz); 7=BY_20 (Divide by 20 = 4MHz); 8=BY_25 (Divide by 25 = 3.2MHz); 9=BY_32 (Divide by 32 = 2.5MHz); 10=BY_40 (Divide by 40 = 2MHz); 11=BY_80 (Divide by 80 = 1MHz)
0x1000 clk_cfg — This register controls the bus clock to *I2C*
  [31:1] RESERVED1 ro — Reads to this field return zero.Writes to this field are ignored.
  [0] ENABLE rw — This field enables or disables the bus clock to *I2C*
    0=DIS (I2C clock disabled); 1=EN (I2C clock disabled)
